# ESP32-C6-LP register map
Vendor: ESPRESSIF SYSTEMS (SHANGHAI) CO., LTD.; Series: ESP32 Series; File version: 2
32-bit RISC-V MCU
CPU: RV32IMAC r0p0, little endian, no MPU, no FPU, 0 interrupt priority bits
Address unit: 32 bits
Registers are 32-bit, read-write, reset 0x0 unless marked. A register's access mark holds for its fields unless they carry their own. Offsets are from the block's base; lines under a group give offsets from that group; [hi:lo] are bit positions; {n}, {i} and the like mark numbered series; 'fields as' and 'values as' point back to an identical list; <NAME> marks a mode.

## Memory map
0x600B0400 LP_CLKRST size 0x34 — LP_CLKRST Peripheral
0x600B0C00 LP_TIMER size 0x4C — Low-power Timer
0x600B1000 LP_AON size 0x5C — LP_AON Peripheral
0x600B1400 LP_UART size 0x84 — Low-power UART (Universal Asynchronous Receiver-Transmitter) Controller
0x600B1800 LP_I2C0 size 0x88 — Low-power I2C (Inter-Integrated Circuit) Controller 0
0x600B1C00 LP_WDT size 0x38 — Low-power Watchdog Timer
0x600B2000 LP_IO size 0x7C — LP_IO Peripheral
0x600B2400 LP_I2C_ANA_MST size 0x1C — LP_I2C_ANA_MST Peripheral
0x600B2800 LP_PERI size 0x28 — LP_PERI Peripheral
0x600B2C00 LP_ANA_PERI size 0x34 — LP_ANA_PERI Peripheral
0x600B3400 LP_TEE size 0x10 — Low-power Trusted Execution Environment
0x600B3800 LP_APM size 0x64 — Low-power Access Permission Management Controller

## Interrupts
7 LP_TIMER
16 LP_UART
17 LP_I2C (LP_I2C0)
18 LP_WDT
19 LP_PERI_TIMEOUT (LP_PERI)
20 LP_APM_M0 (LP_APM)
21 LP_APM_M1 (LP_APM)

## LP_PERI — LP_PERI Peripheral
Base 0x600B2800
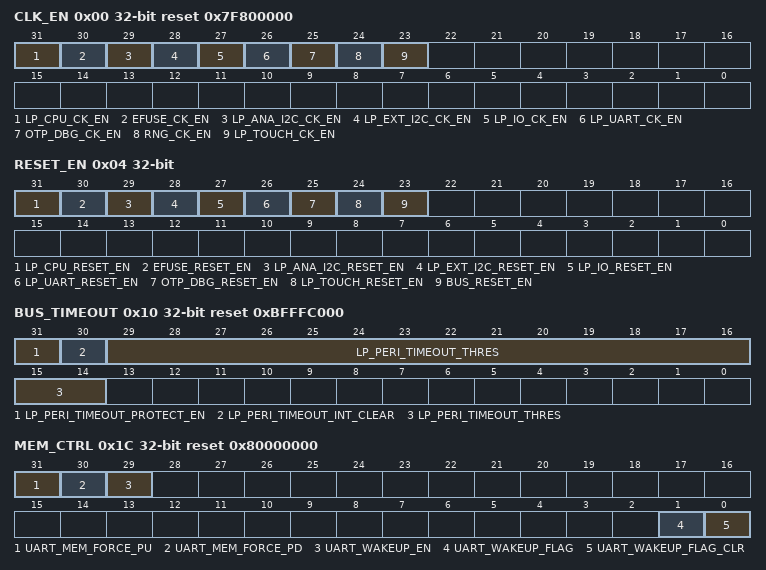
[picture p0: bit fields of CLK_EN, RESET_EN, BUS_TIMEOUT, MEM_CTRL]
0x00 CLK_EN reset 0x7F800000 — need_des
  [31] LP_CPU_CK_EN — need_des
  [30] EFUSE_CK_EN — need_des
  [29] LP_ANA_I2C_CK_EN — need_des
  [28] LP_EXT_I2C_CK_EN — need_des
  [27] LP_IO_CK_EN — need_des
  [26] LP_UART_CK_EN — need_des
  [25] OTP_DBG_CK_EN — need_des
  [24] RNG_CK_EN — need_des
  [23] LP_TOUCH_CK_EN — need_des
0x04 RESET_EN access per field — need_des
  [31] LP_CPU_RESET_EN wo — need_des
  [30] EFUSE_RESET_EN rw — need_des
  [29] LP_ANA_I2C_RESET_EN rw — need_des
  [28] LP_EXT_I2C_RESET_EN rw — need_des
  [27] LP_IO_RESET_EN rw — need_des
  [26] LP_UART_RESET_EN rw — need_des
  [25] OTP_DBG_RESET_EN rw — need_des
  [24] LP_TOUCH_RESET_EN rw — need_des
  [23] BUS_RESET_EN wo — need_des
0x08 RNG_DATA ro — need_des
  [31:0] RND_DATA
0x0C CPU reset 0x80000000 — need_des
  [31] LPCORE_DBGM_UNAVALIABLE
0x10 BUS_TIMEOUT access per field reset 0xBFFFC000 — need_des
  [31] LP_PERI_TIMEOUT_PROTECT_EN rw — need_des
  [30] LP_PERI_TIMEOUT_INT_CLEAR wo — need_des
  [29:14] LP_PERI_TIMEOUT_THRES rw — need_des
0x14 BUS_TIMEOUT_ADDR ro — need_des
  [31:0] LP_PERI_TIMEOUT_ADDR
0x18 BUS_TIMEOUT_UID ro — need_des
  [6:0] LP_PERI_TIMEOUT_UID
0x1C MEM_CTRL access per field reset 0x80000000 — need_des
  [31] UART_MEM_FORCE_PU rw — need_des
  [30] UART_MEM_FORCE_PD rw — need_des
  [29] UART_WAKEUP_EN rw — need_des
  [1] UART_WAKEUP_FLAG rw — need_des
  [0] UART_WAKEUP_FLAG_CLR wo — need_des
0x20 INTERRUPT_SOURCE ro — need_des
  [5:0] LP_INTERRUPT_SOURCE — BIT5~BIT0: pmu_lp_int, modem_lp_int, lp_timer_lp_int, lp_uart_int, lp_i2c_int, lp_io_int
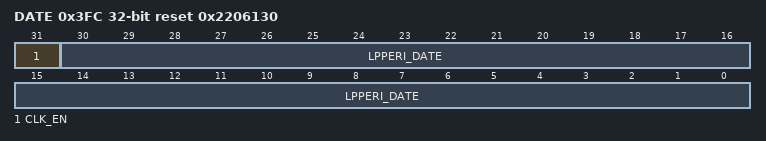
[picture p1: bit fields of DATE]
0x3FC DATE reset 0x2206130 — need_des
  [31] CLK_EN — need_des
  [30:0] LPPERI_DATE — need_des

## LP_ANA_PERI — LP_ANA_PERI Peripheral
Base 0x600B2C00
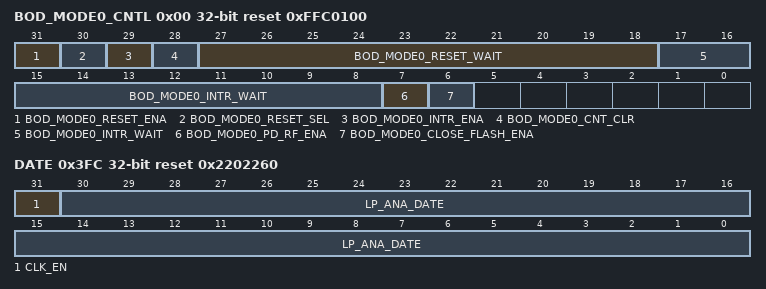
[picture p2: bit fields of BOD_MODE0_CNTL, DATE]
0x00 BOD_MODE0_CNTL reset 0xFFC0100 — need_des
  [31] BOD_MODE0_RESET_ENA — need_des
  [30] BOD_MODE0_RESET_SEL — need_des
  [29] BOD_MODE0_INTR_ENA — need_des
  [28] BOD_MODE0_CNT_CLR — need_des
  [27:18] BOD_MODE0_RESET_WAIT — need_des
  [17:8] BOD_MODE0_INTR_WAIT — need_des
  [7] BOD_MODE0_PD_RF_ENA — need_des
  [6] BOD_MODE0_CLOSE_FLASH_ENA — need_des
0x04 BOD_MODE1_CNTL — need_des
  [31] BOD_MODE1_RESET_ENA
0x08 CK_GLITCH_CNTL — need_des
  [31] CK_GLITCH_RESET_ENA
0x0C FIB_ENABLE reset 0xFFFFFFFF — need_des
  [31:0] ANA_FIB_ENA
0x10 INT_RAW — need_des
  [31] BOD_MODE0_INT_RAW
0x14 INT_ST ro — need_des
  [31] BOD_MODE0_INT_ST
0x18 INT_ENA — need_des
  [31] BOD_MODE0_INT_ENA
0x1C INT_CLR wo — need_des
  [31] BOD_MODE0_INT_CLR
0x20 LP_INT_RAW — need_des
  [31] BOD_MODE0_LP_INT_RAW
0x24 LP_INT_ST ro — need_des
  [31] BOD_MODE0_LP_INT_ST
0x28 LP_INT_ENA — need_des
  [31] BOD_MODE0_LP_INT_ENA
0x2C LP_INT_CLR wo — need_des
  [31] BOD_MODE0_LP_INT_CLR
0x3FC DATE reset 0x2202260 — need_des
  [31] CLK_EN — need_des
  [30:0] LP_ANA_DATE — need_des

## Licence text in the file
Copyright 2024 Espressif Systems (Shanghai) PTE LTD Licensed under the Apache License, Version 2.0 (the "License"); you may not use this file except in compliance with the License. You may obtain a copy of the License at http://www.apache.org/licenses/LICENSE-2.0 Unless required by applicable law or agreed to in writing, software distributed under the License is distributed on an "AS IS" BASIS, WITHOUT WARRANTIES OR CONDITIONS OF ANY KIND, either express or implied. See the License for the specific language governing permissions and limitations under the License.
